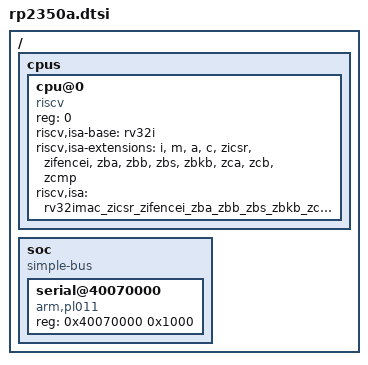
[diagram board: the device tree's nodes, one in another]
// SPDX-License-Identifier: GPL-2.0
/*
 * RP2350A SoC 级设备树（工程按需增量，不一次性堆全）。
 *
 * 00_amowall 故意只给能出 earlycon 的最少内容，并**故意去掉**：
 *   - /cpus 的 timebase-frequency
 *   - cpu@0 的 riscv,cpu-intc（CPU 本地中断控制器）
 * 目的：让内核在启动早期 panic（init_IRQ: "No interrupt controller found."），
 * 本工程验收 = earlycon 出字 + 亲眼看到 panic；修复放到后续工程。
 * serial（PL011）先不给 clocks/interrupts——probe 会失败，日志仍走 earlycon。
 */
/dts-v1/;

/ {
	#address-cells = <1>;
	#size-cells = <1>;

	cpus {
		#address-cells = <1>;
		#size-cells = <0>;

		cpu@0 {
			device_type = "cpu";
			reg = <0>;
			compatible = "riscv";
			riscv,isa-base = "rv32i";
			riscv,isa-extensions = "i", "m", "a", "c", "zicsr",
						 "zifencei", "zba", "zbb", "zbs",
						 "zbkb", "zca", "zcb", "zcmp";
			riscv,isa = "rv32imac_zicsr_zifencei_zba_zbb_zbs_zbkb_zca_zcb_zcmp";

		};
	};

	soc {
		#address-cells = <1>;
		#size-cells = <1>;
		compatible = "simple-bus";
		ranges;

		serial@40070000 {
			compatible = "arm,pl011";
			reg = <0x40070000 0x1000>;
			/* 00_amowall：不加 clocks/interrupts，pl011 真驱动 probe 失败，
			 * earlycon 不受影响（显式地址轮询写寄存器）。 */
		};
	};
};
